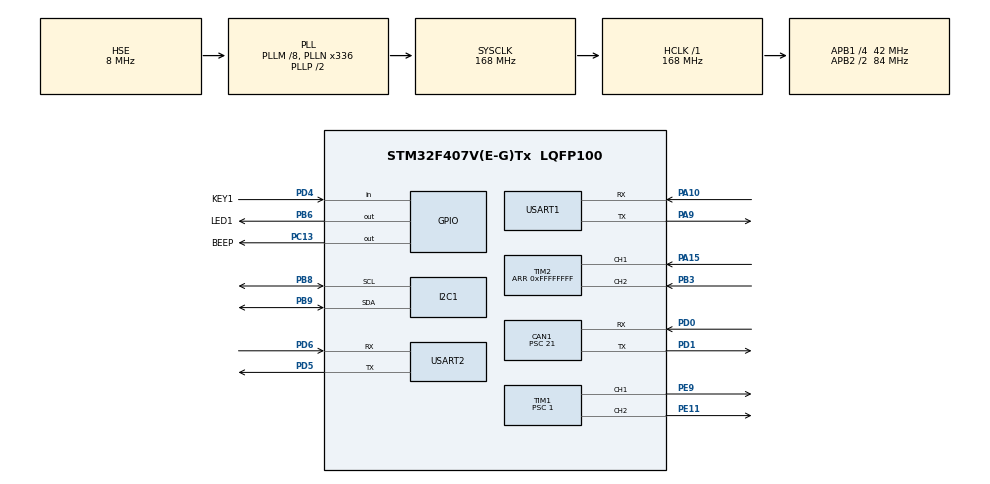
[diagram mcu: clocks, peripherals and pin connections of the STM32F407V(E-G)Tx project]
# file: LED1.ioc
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CAN1.ABOM=ENABLE
CAN1.AWUM=ENABLE
CAN1.BS1=CAN_BS1_15TQ
CAN1.BS2=CAN_BS2_4TQ
CAN1.CalculateBaudRate=100000
CAN1.CalculateTimeBit=10000
CAN1.CalculateTimeQuantum=500.0
CAN1.Prescaler=21
CAN1.SJW=CAN_SJW_1TQ
CAN1.TXFP=ENABLE
Dma.Request0=USART2_TX
Dma.USART2_TX.0.Direction=DMA_MEMORY_TO_PERIPH
Dma.USART2_TX.0.FIFOMode=DMA_FIFOMODE_DISABLE
Dma.USART2_TX.0.Instance=DMA1_Stream6
Dma.USART2_TX.0.MemDataAlignment=DMA_MDATAALIGN_BYTE
Dma.USART2_TX.0.MemInc=DMA_MINC_ENABLE
Dma.USART2_TX.0.Mode=DMA_NORMAL
Dma.USART2_TX.0.PeriphDataAlignment=DMA_PDATAALIGN_BYTE
Dma.USART2_TX.0.PeriphInc=DMA_PINC_DISABLE
Dma.USART2_TX.0.Priority=DMA_PRIORITY_LOW
FREERTOS.Tasks01=defaultTask,24,128,StartDefaultTask,Default,NULL,Dynamic,NULL,NULL;LED1_TASK2,8,128,StartTask02,Default,NULL,Dynamic,NULL,NULL;FENGMING_TASK3,8,128,StartTask03,Default,NULL,Dynamic,NULL,NULL;DIANJI_TASK4,8,128,StartTask04,Default,NULL,Dynamic,NULL,NULL
Mcu.Family=STM32F4
Mcu.Name=STM32F407V(E-G)Tx
Mcu.Package=LQFP100
NVIC.DMA1_Stream6_IRQn=true\:5\:0\:false\:false\:true\:true\:false\:true\:true
NVIC.PriorityGroup=NVIC_PRIORITYGROUP_4
NVIC.USART2_IRQn=true\:5\:0\:false\:false\:true\:true\:true\:true\:true
PA10.Mode=Asynchronous
PA10.Signal=USART1_RX
PA13.Mode=Serial_Wire
PA13.Signal=SYS_JTMS-SWDIO
PA14.Mode=Serial_Wire
PA14.Signal=SYS_JTCK-SWCLK
PA15.Signal=S_TIM2_CH1_ETR
PA9.Mode=Asynchronous
PA9.Signal=USART1_TX
PB3.Signal=S_TIM2_CH2
PB6.GPIO_Label=LED1
PB6.PinState=GPIO_PIN_SET
PB6.Signal=GPIO_Output
PB8.Mode=I2C
PB8.Signal=I2C1_SCL
PB9.Mode=I2C
PB9.Signal=I2C1_SDA
PC13-ANTI_TAMP.GPIO_Label=BEEP
PC13-ANTI_TAMP.PinState=GPIO_PIN_RESET
PC13-ANTI_TAMP.Signal=GPIO_Output
PC14-OSC32_IN.Mode=LSE-External-Oscillator
PC14-OSC32_IN.Signal=RCC_OSC32_IN
PC15-OSC32_OUT.Mode=LSE-External-Oscillator
PC15-OSC32_OUT.Signal=RCC_OSC32_OUT
PD0.Mode=CAN_Activate
PD0.Signal=CAN1_RX
PD1.Mode=CAN_Activate
PD1.Signal=CAN1_TX
PD4.GPIO_Label=KEY1
PD4.GPIO_PuPd=GPIO_PULLUP
PD4.Signal=GPIO_Input
PD5.Mode=Asynchronous
PD5.Signal=USART2_TX
PD6.Mode=Asynchronous
PD6.Signal=USART2_RX
PE11.Signal=S_TIM1_CH2
PE9.Signal=S_TIM1_CH1
PH0-OSC_IN.Mode=HSE-External-Oscillator
PH0-OSC_IN.Signal=RCC_OSC_IN
PH1-OSC_OUT.Mode=HSE-External-Oscillator
PH1-OSC_OUT.Signal=RCC_OSC_OUT
ProjectManager.HeapSize=0x200
ProjectManager.StackSize=0x400
ProjectManager.TargetToolchain=MDK-ARM V5.32
RCC.48MHZClocksFreq_Value=84000000
RCC.AHBFreq_Value=168000000
RCC.APB1CLKDivider=RCC_HCLK_DIV4
RCC.APB1Freq_Value=42000000
RCC.APB1TimFreq_Value=84000000
RCC.APB2CLKDivider=RCC_HCLK_DIV2
RCC.APB2Freq_Value=84000000
RCC.APB2TimFreq_Value=168000000
RCC.CortexFreq_Value=168000000
RCC.HCLKFreq_Value=168000000
RCC.HSE_VALUE=8000000
RCC.HSI_VALUE=16000000
RCC.PLLM=8
RCC.PLLN=336
RCC.PLLSourceVirtual=RCC_PLLSOURCE_HSE
RCC.SYSCLKFreq_VALUE=168000000
RCC.SYSCLKSource=RCC_SYSCLKSOURCE_PLLCLK
RCC.VCOOutputFreq_Value=336000000
SH.S_TIM1_CH1.0=TIM1_CH1,PWM Generation1 CH1
SH.S_TIM1_CH2.0=TIM1_CH2,PWM Generation2 CH2
SH.S_TIM2_CH1_ETR.0=TIM2_CH1,Encoder_Interface
SH.S_TIM2_CH2.0=TIM2_CH2,Encoder_Interface
TIM1.Channel-PWM\ Generation1\ CH1=TIM_CHANNEL_1
TIM1.Channel-PWM\ Generation2\ CH2=TIM_CHANNEL_2
TIM1.Period=4199
TIM1.Prescaler=1
TIM2.EncoderMode=TIM_ENCODERMODE_TI12
TIM2.IC1Filter=6
TIM2.IC2Filter=6
TIM2.IC2Prescaler=TIM_ICPSC_DIV1
TIM2.Period=0xFFFFFFFF
USART1.VirtualMode=VM_ASYNC
USART2.VirtualMode=VM_ASYNC
VP_CRC_VS_CRC.Mode=CRC_Activate
VP_FREERTOS_VS_CMSIS_V2.Mode=CMSIS_V2
board=custom

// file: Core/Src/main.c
/* USER CODE BEGIN Header */
/**
  ******************************************************************************
  * @file           : main.c
  * @brief          : Main program body
  ******************************************************************************
  * @attention
  *
  * Copyright (c) 2026 STMicroelectronics.
  * All rights reserved.
  *
  * This software is licensed under terms that can be found in the LICENSE file
  * in the root directory of this software component.
  * If no LICENSE file comes with this software, it is provided AS-IS.
  *
  ******************************************************************************
  */
/* USER CODE END Header */
#include "main.h"
#include "cmsis_os.h"
#include "can.h"
#include "crc.h"
#include "dma.h"
#include "i2c.h"
#include "tim.h"
#include "usart.h"
#include "gpio.h"

/* USER CODE BEGIN Includes */
#include "mpu.h"
#include "dianji.h"
/* USER CODE END Includes */

void SystemClock_Config(void);
void MX_FREERTOS_Init(void);

int main(void)
{

  /* MCU Configuration--------------------------------------------------------*/

  /* Reset of all peripherals, Initializes the Flash interface and the Systick. */
  HAL_Init();

  /* Configure the system clock */
  SystemClock_Config();

  /* Initialize all configured peripherals */
  MX_GPIO_Init();
  MX_DMA_Init();
  MX_I2C1_Init();
  MX_USART1_UART_Init();
  MX_TIM2_Init();
  MX_TIM1_Init();
  MX_USART2_UART_Init();
  MX_CAN1_Init();
  MX_CRC_Init();
  /* USER CODE BEGIN 2 */
	mpu_init();

  /* USER CODE END 2 */

  /* Init scheduler */
  osKernelInitialize();

  /* Call init function for freertos objects (in freertos.c) */
  MX_FREERTOS_Init();

  /* Start scheduler */
  osKernelStart();

  /* We should never get here as control is now taken by the scheduler */
  /* Infinite loop */
  while (1)
  {

  }
}

void SystemClock_Config(void)
{
  RCC_OscInitTypeDef RCC_OscInitStruct = {0};
  RCC_ClkInitTypeDef RCC_ClkInitStruct = {0};

  /** Configure the main internal regulator output voltage
  */
  __HAL_RCC_PWR_CLK_ENABLE();
  __HAL_PWR_VOLTAGESCALING_CONFIG(PWR_REGULATOR_VOLTAGE_SCALE1);

  /** Initializes the RCC Oscillators according to the specified parameters
  * in the RCC_OscInitTypeDef structure.
  */
  RCC_OscInitStruct.OscillatorType = RCC_OSCILLATORTYPE_HSE;
  RCC_OscInitStruct.HSEState = RCC_HSE_ON;
  RCC_OscInitStruct.PLL.PLLState = RCC_PLL_ON;
  RCC_OscInitStruct.PLL.PLLSource = RCC_PLLSOURCE_HSE;
  RCC_OscInitStruct.PLL.PLLM = 8;
  RCC_OscInitStruct.PLL.PLLN = 336;
  RCC_OscInitStruct.PLL.PLLP = RCC_PLLP_DIV2;
  RCC_OscInitStruct.PLL.PLLQ = 4;
  if (HAL_RCC_OscConfig(&RCC_OscInitStruct) != HAL_OK)
  {
    Error_Handler();
  }

  /** Initializes the CPU, AHB and APB buses clocks
  */
  RCC_ClkInitStruct.ClockType = RCC_CLOCKTYPE_HCLK|RCC_CLOCKTYPE_SYSCLK
                              |RCC_CLOCKTYPE_PCLK1|RCC_CLOCKTYPE_PCLK2;
  RCC_ClkInitStruct.SYSCLKSource = RCC_SYSCLKSOURCE_PLLCLK;
  RCC_ClkInitStruct.AHBCLKDivider = RCC_SYSCLK_DIV1;
  RCC_ClkInitStruct.APB1CLKDivider = RCC_HCLK_DIV4;
  RCC_ClkInitStruct.APB2CLKDivider = RCC_HCLK_DIV2;

  if (HAL_RCC_ClockConfig(&RCC_ClkInitStruct, FLASH_LATENCY_5) != HAL_OK)
  {
    Error_Handler();
  }
}

void Error_Handler(void)
{
  __disable_irq();
  while (1)
  {
  }
}

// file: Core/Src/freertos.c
/* USER CODE BEGIN Header */
/**
  ******************************************************************************
  * File Name          : freertos.c
  * Description        : Code for freertos applications
  ******************************************************************************
  * @attention
  *
  * Copyright (c) 2026 STMicroelectronics.
  * All rights reserved.
  *
  * This software is licensed under terms that can be found in the LICENSE file
  * in the root directory of this software component.
  * If no LICENSE file comes with this software, it is provided AS-IS.
  *
  ******************************************************************************
  */
/* USER CODE END Header */

#include "FreeRTOS.h"
#include "task.h"
#include "main.h"
#include "cmsis_os.h"

/* USER CODE BEGIN Includes */

#include "mpu.h"
#include "BEEP.h"
#include <stdio.h>
#include "dianji.h"
#include "usart.h"
#include "can.h"

/* USER CODE END Includes */

/* Definitions for defaultTask */
osThreadId_t defaultTaskHandle;
const osThreadAttr_t defaultTask_attributes = {
  .name = "defaultTask",
  .stack_size = 128 * 4,
  .priority = (osPriority_t) osPriorityNormal,
};
/* Definitions for LED1_TASK2 */
osThreadId_t LED1_TASK2Handle;
const osThreadAttr_t LED1_TASK2_attributes = {
  .name = "LED1_TASK2",
  .stack_size = 128 * 4,
  .priority = (osPriority_t) osPriorityLow,
};
/* Definitions for FENGMING_TASK3 */
osThreadId_t FENGMING_TASK3Handle;
const osThreadAttr_t FENGMING_TASK3_attributes = {
  .name = "FENGMING_TASK3",
  .stack_size = 128 * 4,
  .priority = (osPriority_t) osPriorityLow,
};
/* Definitions for DIANJI_TASK4 */
osThreadId_t DIANJI_TASK4Handle;
const osThreadAttr_t DIANJI_TASK4_attributes = {
  .name = "DIANJI_TASK4",
  .stack_size = 128 * 4,
  .priority = (osPriority_t) osPriorityAboveNormal,
};

void StartDefaultTask(void *argument);
void StartTask02(void *argument);
void StartTask03(void *argument);
void StartTask04(void *argument);

void MX_FREERTOS_Init(void); /* (MISRA C 2004 rule 8.1) */

void MX_FREERTOS_Init(void) {

  /* Create the thread(s) */
  /* creation of defaultTask */
  defaultTaskHandle = osThreadNew(StartDefaultTask, NULL, &defaultTask_attributes);

  /* creation of LED1_TASK2 */
  LED1_TASK2Handle = osThreadNew(StartTask02, NULL, &LED1_TASK2_attributes);

  /* creation of FENGMING_TASK3 */
  FENGMING_TASK3Handle = osThreadNew(StartTask03, NULL, &FENGMING_TASK3_attributes);

  /* creation of DIANJI_TASK4 */
  DIANJI_TASK4Handle = osThreadNew(StartTask04, NULL, &DIANJI_TASK4_attributes);

}

void StartDefaultTask(void *argument)
{
  /* USER CODE BEGIN StartDefaultTask */
  /* Infinite loop */
 //beep_on_time(3, 100);
 // int16_t ax,ay,az,gx,gy,gz;
  for(;;)
  {
  // mpu_get_data(&ax,&ay,&az,&gx,&gy,&gz);
    // printf("AX:%d AY:%d AZ:%d | GX:%d GY:%d GZ:%d \r\n",ax,ay,az,gx,gy,gz);

      vTaskDelay(2000); // 每半秒打印一次，串口不会刷屏
    osDelay(1);
  }
  /* USER CODE END StartDefaultTask */
}

void StartTask02(void *argument)
{
  /* USER CODE BEGIN StartTask02 */
  /* Infinite loop */
  for(;;)
  {
    HAL_GPIO_WritePin(LED1_GPIO_Port, LED1_Pin, GPIO_PIN_RESET);
    vTaskDelay(500);
    HAL_GPIO_WritePin(LED1_GPIO_Port, LED1_Pin, GPIO_PIN_SET);
    vTaskDelay(500);
    osDelay(1);
  }
  /* USER CODE END StartTask02 */
}

void StartTask03(void *argument)
{
  /* USER CODE BEGIN StartTask03 */
  /* Infinite loop */
  for(;;)
  {
    // if(HAL_GPIO_ReadPin(KEY1_GPIO_Port, KEY1_Pin) == GPIO_PIN_RESET)
    // {
    //   beep_on_time(2, 100);
    //   vTaskDelay(500);
    // }

    osDelay(1);
  }
  /* USER CODE END StartTask03 */
}

void StartTask04(void *argument)
{
    TickType_t last_wake_tick;
    float rpm;
    int32_t delta_count;
    int32_t rpm_integer;
    uint8_t print_divider = 0;

    Dianji_Init();

    /* 先使用30%占空比，电机必须悬空测试 */
    Dianji_SetDuty(800);

    if(CAN_MotorSpeedStart() != HAL_OK)
    {
        Error_Handler();
    }

    last_wake_tick = xTaskGetTickCount();

    for(;;)
    {
        vTaskDelayUntil(&last_wake_tick,
                        pdMS_TO_TICKS(50U));

        /* 每50ms读取一次编码器并计算RPM */
        Dianji_Update(50U);

        delta_count = Dianji_GetDeltaCount();
        rpm = Dianji_GetRPM();

        /*
         * 不直接使用 printf("%.1f")，
         * 避免 Keil 没有启用浮点 printf。
         */
        if(rpm >= 0.0f)
        {
            rpm_integer = (int32_t)(rpm + 0.5f);
        }
        else
        {
            rpm_integer = (int32_t)(rpm - 0.5f);
        }

        /*
         * 每4次打印一次：
         * 4 × 50ms = 200ms
         */
        print_divider++;

        if(print_divider >= 4U)
        {
            print_divider = 0U;

            printf("ENC:%ld RPM:%ld\r\n",
                   (long)delta_count,
                   (long)rpm_integer);
        }

        /* 把转速发送给F103 */
        HAL_StatusTypeDef can_result;

can_result = CAN_SendMotorSpeed(rpm);

if(can_result == HAL_BUSY)
{
    printf("CAN BUSY\r\n");
}
else if(can_result != HAL_OK)
{
    printf("CAN ERROR:%lu\r\n",
           (unsigned long)HAL_CAN_GetError(&hcan1));
}
    }

  /* USER CODE END StartTask04 */
}
